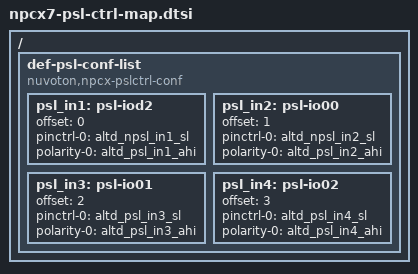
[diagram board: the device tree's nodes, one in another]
/*
 * Copyright (c) 2021 Nuvoton Technology Corporation.
 *
 * SPDX-License-Identifier: Apache-2.0
 */

/ {
	def-psl-conf-list {
		compatible = "nuvoton,npcx-pslctrl-conf";

		/* PSL input IO configurations */
		psl_in1: psl-iod2 {
			offset = <0>; /* PSL_IN1/PIND2 */
			pinctrl-0 = <&altd_npsl_in1_sl>;
			polarity-0 = <&altd_psl_in1_ahi>;
		};
		psl_in2: psl-io00 {
			offset = <1>; /* PSL_IN2/PIN00 */
			pinctrl-0 = <&altd_npsl_in2_sl>;
			polarity-0 = <&altd_psl_in2_ahi>;
		};
		psl_in3: psl-io01 {
			offset = <2>; /* PSL_IN3/PIN01 */
			pinctrl-0 = <&altd_psl_in3_sl>;
			polarity-0 = <&altd_psl_in3_ahi>;
		};
		psl_in4: psl-io02 {
			offset = <3>; /* PSL_IN4/PIN02 */
			pinctrl-0 = <&altd_psl_in4_sl>;
			polarity-0 = <&altd_psl_in4_ahi>;
		};
	};
};
